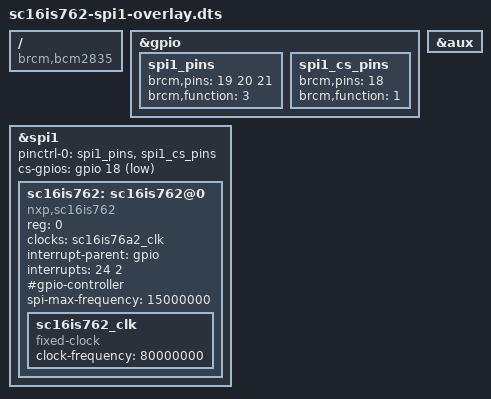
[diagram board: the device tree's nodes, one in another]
/dts-v1/;
/plugin/;

/ {
	compatible = "brcm,bcm2835", "brcm,bcm2708", "brcm,bcm2709";

	fragment@0 {
		target = <&gpio>;
		__overlay__ {
			spi1_pins: spi1_pins {
				brcm,pins = <19 20 21>;
				brcm,function = <3>; /* alt4 */
			};

			spi1_cs_pins: spi1_cs_pins {
				brcm,pins = <18>;
				brcm,function = <1>; /* output */
			};
		};
	};

	fragment@1 {
		target = <&spi1>;
		frag1: __overlay__ {
			#address-cells = <1>;
			#size-cells = <0>;
			pinctrl-names = "default";
			pinctrl-0 = <&spi1_pins &spi1_cs_pins>;
			cs-gpios = <&gpio 18 1>;
			status = "okay";

			sc16is762: sc16is762@0 {
				compatible = "nxp,sc16is762";
				reg = <0>; /* CE0 */
				clocks = <&sc16is76a2_clk>;
				interrupt-parent = <&gpio>;
				interrupts = <24 2>; /* IRQ_TYPE_EDGE_FALLING */
				#gpio-controller;
				#gpio-cells = <2>;
				spi-max-frequency = <15000000>;

				sc16is762_clk: sc16is762_clk {
					compatible = "fixed-clock";
					#clock-cells = <0>;
					clock-frequency = <80000000>;
				};
			};
		};
	};

	fragment@2 {
		target = <&aux>;
		__overlay__ {
			status = "okay";
		};
	};

    __overrides__ {
      int_pin = <&sc16is762>,"interrupts:0";
    };
};
